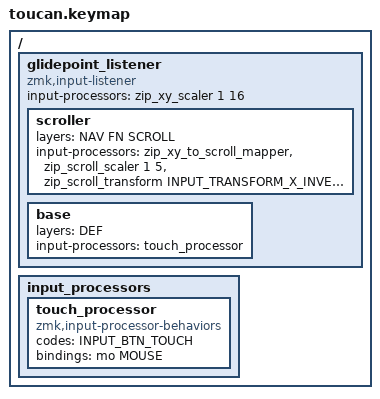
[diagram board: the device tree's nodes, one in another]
#define CONFIG_WIRELESS

// 6th layer
#define SCROLL 6

// Define to indicate we have a physical mouse/touchpad
#define HAS_MOUSE

#include "zmk-helpers/key-labels/42.h"
#include "base.keymap"
#include "scroll_layer.h"
#include "zmk_studio.h"

/ {
    glidepoint_listener: glidepoint_listener {
        compatible = "zmk,input-listener";

        input-processors = <
            &zip_xy_scaler 1 16 // lowering to 0.0625x
            >;
        
        scroller {
            layers = <NAV FN SCROLL>;
            input-processors = <
                &zip_xy_to_scroll_mapper
                &zip_scroll_scaler 1 5
                &zip_scroll_transform INPUT_TRANSFORM_X_INVERT
            >;
        };
        base {
            layers = <DEF>;
            input-processors = <
                &touch_processor    
            >;        
        };        
    };

    // FIXME turn on smooth scrolling
    input_processors {
        touch_processor: touch_processor {
            compatible = "zmk,input-processor-behaviors";
            #input-processor-cells = <0>;
 
            codes = <INPUT_BTN_TOUCH>;      // watch for the 'touch' pseudo button
            bindings  = <&mo MOUSE>;            // Activate Layer 4 while held &mo 4
        };
    };
};
